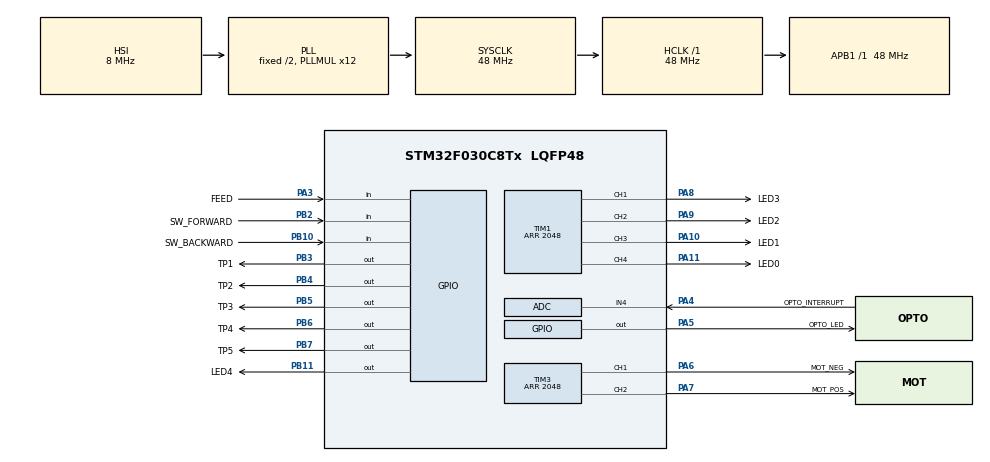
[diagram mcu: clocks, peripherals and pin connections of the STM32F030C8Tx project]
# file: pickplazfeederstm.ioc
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Mcu.Family=STM32F0
Mcu.Name=STM32F030C8Tx
Mcu.Package=LQFP48
PA10.GPIO_Label=LED1
PA10.Signal=S_TIM1_CH3
PA11.GPIO_Label=LED0
PA11.Signal=S_TIM1_CH4
PA13.Mode=Serial_Wire
PA13.Signal=SYS_SWDIO
PA14.Mode=Serial_Wire
PA14.Signal=SYS_SWCLK
PA3.GPIO_Label=FEED
PA3.Signal=GPIO_Input
PA4.GPIO_Label=OPTO_INTERRUPT
PA4.Mode=IN4
PA4.Signal=ADC_IN4
PA5.GPIO_Label=OPTO_LED
PA5.Signal=GPIO_Output
PA6.GPIO_Label=MOT_NEG
PA6.Signal=S_TIM3_CH1
PA7.GPIO_Label=MOT_POS
PA7.Signal=S_TIM3_CH2
PA8.GPIO_Label=LED3
PA8.Signal=S_TIM1_CH1
PA9.GPIO_Label=LED2
PA9.Signal=S_TIM1_CH2
PB10.GPIO_Label=SW_BACKWARD
PB10.Signal=GPIO_Input
PB11.GPIO_Label=LED4
PB11.Signal=GPIO_Output
PB2.GPIO_Label=SW_FORWARD
PB2.Signal=GPIO_Input
PB3.GPIO_Label=TP1
PB3.Signal=GPIO_Output
PB4.GPIO_Label=TP2
PB4.Signal=GPIO_Output
PB5.GPIO_Label=TP3
PB5.Signal=GPIO_Output
PB6.GPIO_Label=TP4
PB6.Signal=GPIO_Output
PB7.GPIO_Label=TP5
PB7.Signal=GPIO_Output
ProjectManager.HeapSize=0x200
ProjectManager.StackSize=0x400
ProjectManager.TargetToolchain=STM32CubeIDE
RCC.AHBFreq_Value=48000000
RCC.APB1Freq_Value=48000000
RCC.APB1TimFreq_Value=48000000
RCC.HCLKFreq_Value=48000000
RCC.PLLMUL=RCC_PLL_MUL12
RCC.SYSCLKFreq_VALUE=48000000
RCC.SYSCLKSource=RCC_SYSCLKSOURCE_PLLCLK
SH.S_TIM1_CH1.0=TIM1_CH1,PWM Generation1 CH1
SH.S_TIM1_CH2.0=TIM1_CH2,PWM Generation2 CH2
SH.S_TIM1_CH3.0=TIM1_CH3,PWM Generation3 CH3
SH.S_TIM1_CH4.0=TIM1_CH4,PWM Generation4 CH4
SH.S_TIM3_CH1.0=TIM3_CH1,PWM Generation1 CH1
SH.S_TIM3_CH2.0=TIM3_CH2,PWM Generation2 CH2
TIM1.AutoReloadPreload=TIM_AUTORELOAD_PRELOAD_ENABLE
TIM1.Channel-PWM\ Generation1\ CH1=TIM_CHANNEL_1
TIM1.Channel-PWM\ Generation2\ CH2=TIM_CHANNEL_2
TIM1.Channel-PWM\ Generation3\ CH3=TIM_CHANNEL_3
TIM1.Channel-PWM\ Generation4\ CH4=TIM_CHANNEL_4
TIM1.Period=2048
TIM3.AutoReloadPreload=TIM_AUTORELOAD_PRELOAD_ENABLE
TIM3.Channel-PWM\ Generation1\ CH1=TIM_CHANNEL_1
TIM3.Channel-PWM\ Generation2\ CH2=TIM_CHANNEL_2
TIM3.Period=2048
board=custom

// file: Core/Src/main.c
/* USER CODE BEGIN Header */
/**
  ******************************************************************************
  * @file           : main.c
  * @brief          : Main program body
  ******************************************************************************
  * @attention
  *
  * Copyright (c) 2022 STMicroelectronics.
  * All rights reserved.
  *
  * This software is licensed under terms that can be found in the LICENSE file
  * in the root directory of this software component.
  * If no LICENSE file comes with this software, it is provided AS-IS.
  *
  ******************************************************************************
  */
/* USER CODE END Header */
#include "main.h"

 ADC_HandleTypeDef hadc;

TIM_HandleTypeDef htim1;
TIM_HandleTypeDef htim3;

void SystemClock_Config(void);
static void MX_GPIO_Init(void);
static void MX_ADC_Init(void);
static void MX_TIM1_Init(void);
static void MX_TIM3_Init(void);

int main(void)
{

  /* MCU Configuration--------------------------------------------------------*/

  /* Reset of all peripherals, Initializes the Flash interface and the Systick. */
  HAL_Init();

  /* Configure the system clock */
  SystemClock_Config();

  /* Initialize all configured peripherals */
  MX_GPIO_Init();
  MX_ADC_Init();
  MX_TIM1_Init();
  MX_TIM3_Init();
  /* USER CODE BEGIN 2 */
  app_init();

  /* USER CODE END 2 */

  /* Infinite loop */
  /* USER CODE BEGIN WHILE */
  while (1)
  {
	  __WFI();
    /* USER CODE END WHILE */

  }
}

void SystemClock_Config(void)
{
  RCC_OscInitTypeDef RCC_OscInitStruct = {0};
  RCC_ClkInitTypeDef RCC_ClkInitStruct = {0};

  /** Initializes the RCC Oscillators according to the specified parameters
  * in the RCC_OscInitTypeDef structure.
  */
  RCC_OscInitStruct.OscillatorType = RCC_OSCILLATORTYPE_HSI|RCC_OSCILLATORTYPE_HSI14;
  RCC_OscInitStruct.HSIState = RCC_HSI_ON;
  RCC_OscInitStruct.HSI14State = RCC_HSI14_ON;
  RCC_OscInitStruct.HSICalibrationValue = RCC_HSICALIBRATION_DEFAULT;
  RCC_OscInitStruct.HSI14CalibrationValue = 16;
  RCC_OscInitStruct.PLL.PLLState = RCC_PLL_ON;
  RCC_OscInitStruct.PLL.PLLSource = RCC_PLLSOURCE_HSI;
  RCC_OscInitStruct.PLL.PLLMUL = RCC_PLL_MUL12;
  RCC_OscInitStruct.PLL.PREDIV = RCC_PREDIV_DIV1;
  if (HAL_RCC_OscConfig(&RCC_OscInitStruct) != HAL_OK)
  {
    Error_Handler();
  }

  /** Initializes the CPU, AHB and APB buses clocks
  */
  RCC_ClkInitStruct.ClockType = RCC_CLOCKTYPE_HCLK|RCC_CLOCKTYPE_SYSCLK
                              |RCC_CLOCKTYPE_PCLK1;
  RCC_ClkInitStruct.SYSCLKSource = RCC_SYSCLKSOURCE_PLLCLK;
  RCC_ClkInitStruct.AHBCLKDivider = RCC_SYSCLK_DIV1;
  RCC_ClkInitStruct.APB1CLKDivider = RCC_HCLK_DIV1;

  if (HAL_RCC_ClockConfig(&RCC_ClkInitStruct, FLASH_LATENCY_1) != HAL_OK)
  {
    Error_Handler();
  }
}

static void MX_ADC_Init(void)
{

  ADC_ChannelConfTypeDef sConfig = {0};

  /** Configure the global features of the ADC (Clock, Resolution, Data Alignment and number of conversion)
  */
  hadc.Instance = ADC1;
  hadc.Init.ClockPrescaler = ADC_CLOCK_ASYNC_DIV1;
  hadc.Init.Resolution = ADC_RESOLUTION_12B;
  hadc.Init.DataAlign = ADC_DATAALIGN_RIGHT;
  hadc.Init.ScanConvMode = ADC_SCAN_DIRECTION_FORWARD;
  hadc.Init.EOCSelection = ADC_EOC_SINGLE_CONV;
  hadc.Init.LowPowerAutoWait = DISABLE;
  hadc.Init.LowPowerAutoPowerOff = DISABLE;
  hadc.Init.ContinuousConvMode = DISABLE;
  hadc.Init.DiscontinuousConvMode = DISABLE;
  hadc.Init.ExternalTrigConv = ADC_SOFTWARE_START;
  hadc.Init.ExternalTrigConvEdge = ADC_EXTERNALTRIGCONVEDGE_NONE;
  hadc.Init.DMAContinuousRequests = DISABLE;
  hadc.Init.Overrun = ADC_OVR_DATA_PRESERVED;
  if (HAL_ADC_Init(&hadc) != HAL_OK)
  {
    Error_Handler();
  }

  /** Configure for the selected ADC regular channel to be converted.
  */
  sConfig.Channel = ADC_CHANNEL_4;
  sConfig.Rank = ADC_RANK_CHANNEL_NUMBER;
  sConfig.SamplingTime = ADC_SAMPLETIME_1CYCLE_5;
  if (HAL_ADC_ConfigChannel(&hadc, &sConfig) != HAL_OK)
  {
    Error_Handler();
  }

}

static void MX_TIM1_Init(void)
{

  TIM_MasterConfigTypeDef sMasterConfig = {0};
  TIM_OC_InitTypeDef sConfigOC = {0};
  TIM_BreakDeadTimeConfigTypeDef sBreakDeadTimeConfig = {0};

  htim1.Instance = TIM1;
  htim1.Init.Prescaler = 0;
  htim1.Init.CounterMode = TIM_COUNTERMODE_UP;
  htim1.Init.Period = 2048;
  htim1.Init.ClockDivision = TIM_CLOCKDIVISION_DIV1;
  htim1.Init.RepetitionCounter = 0;
  htim1.Init.AutoReloadPreload = TIM_AUTORELOAD_PRELOAD_ENABLE;
  if (HAL_TIM_PWM_Init(&htim1) != HAL_OK)
  {
    Error_Handler();
  }
  sMasterConfig.MasterOutputTrigger = TIM_TRGO_RESET;
  sMasterConfig.MasterSlaveMode = TIM_MASTERSLAVEMODE_DISABLE;
  if (HAL_TIMEx_MasterConfigSynchronization(&htim1, &sMasterConfig) != HAL_OK)
  {
    Error_Handler();
  }
  sConfigOC.OCMode = TIM_OCMODE_PWM1;
  sConfigOC.Pulse = 0;
  sConfigOC.OCPolarity = TIM_OCPOLARITY_HIGH;
  sConfigOC.OCNPolarity = TIM_OCNPOLARITY_HIGH;
  sConfigOC.OCFastMode = TIM_OCFAST_DISABLE;
  sConfigOC.OCIdleState = TIM_OCIDLESTATE_RESET;
  sConfigOC.OCNIdleState = TIM_OCNIDLESTATE_RESET;
  if (HAL_TIM_PWM_ConfigChannel(&htim1, &sConfigOC, TIM_CHANNEL_1) != HAL_OK)
  {
    Error_Handler();
  }
  if (HAL_TIM_PWM_ConfigChannel(&htim1, &sConfigOC, TIM_CHANNEL_2) != HAL_OK)
  {
    Error_Handler();
  }
  if (HAL_TIM_PWM_ConfigChannel(&htim1, &sConfigOC, TIM_CHANNEL_3) != HAL_OK)
  {
    Error_Handler();
  }
  if (HAL_TIM_PWM_ConfigChannel(&htim1, &sConfigOC, TIM_CHANNEL_4) != HAL_OK)
  {
    Error_Handler();
  }
  sBreakDeadTimeConfig.OffStateRunMode = TIM_OSSR_DISABLE;
  sBreakDeadTimeConfig.OffStateIDLEMode = TIM_OSSI_DISABLE;
  sBreakDeadTimeConfig.LockLevel = TIM_LOCKLEVEL_OFF;
  sBreakDeadTimeConfig.DeadTime = 0;
  sBreakDeadTimeConfig.BreakState = TIM_BREAK_DISABLE;
  sBreakDeadTimeConfig.BreakPolarity = TIM_BREAKPOLARITY_HIGH;
  sBreakDeadTimeConfig.AutomaticOutput = TIM_AUTOMATICOUTPUT_DISABLE;
  if (HAL_TIMEx_ConfigBreakDeadTime(&htim1, &sBreakDeadTimeConfig) != HAL_OK)
  {
    Error_Handler();
  }
  HAL_TIM_MspPostInit(&htim1);

}

static void MX_TIM3_Init(void)
{

  TIM_MasterConfigTypeDef sMasterConfig = {0};
  TIM_OC_InitTypeDef sConfigOC = {0};

  htim3.Instance = TIM3;
  htim3.Init.Prescaler = 0;
  htim3.Init.CounterMode = TIM_COUNTERMODE_UP;
  htim3.Init.Period = 2048;
  htim3.Init.ClockDivision = TIM_CLOCKDIVISION_DIV1;
  htim3.Init.AutoReloadPreload = TIM_AUTORELOAD_PRELOAD_ENABLE;
  if (HAL_TIM_PWM_Init(&htim3) != HAL_OK)
  {
    Error_Handler();
  }
  sMasterConfig.MasterOutputTrigger = TIM_TRGO_RESET;
  sMasterConfig.MasterSlaveMode = TIM_MASTERSLAVEMODE_DISABLE;
  if (HAL_TIMEx_MasterConfigSynchronization(&htim3, &sMasterConfig) != HAL_OK)
  {
    Error_Handler();
  }
  sConfigOC.OCMode = TIM_OCMODE_PWM1;
  sConfigOC.Pulse = 0;
  sConfigOC.OCPolarity = TIM_OCPOLARITY_HIGH;
  sConfigOC.OCFastMode = TIM_OCFAST_DISABLE;
  if (HAL_TIM_PWM_ConfigChannel(&htim3, &sConfigOC, TIM_CHANNEL_1) != HAL_OK)
  {
    Error_Handler();
  }
  if (HAL_TIM_PWM_ConfigChannel(&htim3, &sConfigOC, TIM_CHANNEL_2) != HAL_OK)
  {
    Error_Handler();
  }
  HAL_TIM_MspPostInit(&htim3);

}

static void MX_GPIO_Init(void)
{
  GPIO_InitTypeDef GPIO_InitStruct = {0};

  /* GPIO Ports Clock Enable */
  __HAL_RCC_GPIOA_CLK_ENABLE();
  __HAL_RCC_GPIOB_CLK_ENABLE();

  /*Configure GPIO pin Output Level */
  HAL_GPIO_WritePin(OPTO_LED_GPIO_Port, OPTO_LED_Pin, GPIO_PIN_RESET);

  /*Configure GPIO pin Output Level */
  HAL_GPIO_WritePin(GPIOB, LED4_Pin|TP1_Pin|TP2_Pin|TP3_Pin
                          |TP4_Pin|TP5_Pin, GPIO_PIN_RESET);

  /*Configure GPIO pin : FEED_Pin */
  GPIO_InitStruct.Pin = FEED_Pin;
  GPIO_InitStruct.Mode = GPIO_MODE_INPUT;
  GPIO_InitStruct.Pull = GPIO_NOPULL;
  HAL_GPIO_Init(FEED_GPIO_Port, &GPIO_InitStruct);

  /*Configure GPIO pin : OPTO_LED_Pin */
  GPIO_InitStruct.Pin = OPTO_LED_Pin;
  GPIO_InitStruct.Mode = GPIO_MODE_OUTPUT_PP;
  GPIO_InitStruct.Pull = GPIO_NOPULL;
  GPIO_InitStruct.Speed = GPIO_SPEED_FREQ_LOW;
  HAL_GPIO_Init(OPTO_LED_GPIO_Port, &GPIO_InitStruct);

  /*Configure GPIO pins : SW_FORWARD_Pin SW_BACKWARD_Pin */
  GPIO_InitStruct.Pin = SW_FORWARD_Pin|SW_BACKWARD_Pin;
  GPIO_InitStruct.Mode = GPIO_MODE_INPUT;
  GPIO_InitStruct.Pull = GPIO_NOPULL;
  HAL_GPIO_Init(GPIOB, &GPIO_InitStruct);

  /*Configure GPIO pins : LED4_Pin TP1_Pin TP2_Pin TP3_Pin
                           TP4_Pin TP5_Pin */
  GPIO_InitStruct.Pin = LED4_Pin|TP1_Pin|TP2_Pin|TP3_Pin
                          |TP4_Pin|TP5_Pin;
  GPIO_InitStruct.Mode = GPIO_MODE_OUTPUT_PP;
  GPIO_InitStruct.Pull = GPIO_NOPULL;
  GPIO_InitStruct.Speed = GPIO_SPEED_FREQ_LOW;
  HAL_GPIO_Init(GPIOB, &GPIO_InitStruct);

}

void Error_Handler(void)
{
  __disable_irq();
  while (1)
  {
  }
}
